# iom480ae register map
Registers are 32-bit, access not given, no defined reset value unless marked. A register's access mark holds for its fields unless they carry their own. Addresses are absolute; registers are grouped by the start of their names; [hi:lo] are bit positions.

## UUART0
0x400D0000 UUART0_UUART_CTL
  [2:0] FUNMODE
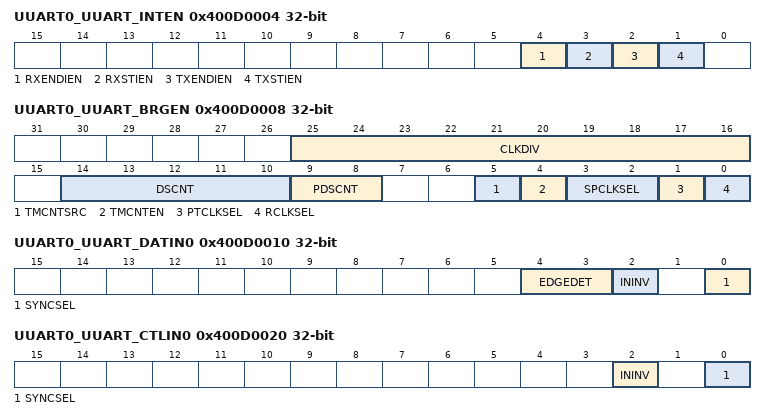
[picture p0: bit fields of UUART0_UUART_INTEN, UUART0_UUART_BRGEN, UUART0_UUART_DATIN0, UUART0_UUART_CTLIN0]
0x400D0004 UUART0_UUART_INTEN
  [4] RXENDIEN, [3] RXSTIEN, [2] TXENDIEN, [1] TXSTIEN
0x400D0008 UUART0_UUART_BRGEN
  [25:16] CLKDIV, [14:10] DSCNT, [9:8] PDSCNT, [5] TMCNTSRC, [4] TMCNTEN, [3:2] SPCLKSEL, [1] PTCLKSEL, [0] RCLKSEL
0x400D0010 UUART0_UUART_DATIN0
  [4:3] EDGEDET, [2] ININV, [0] SYNCSEL
0x400D0020 UUART0_UUART_CTLIN0
  [2] ININV, [0] SYNCSEL
0x400D0028 UUART0_UUART_CLKIN
  [0] SYNCSEL
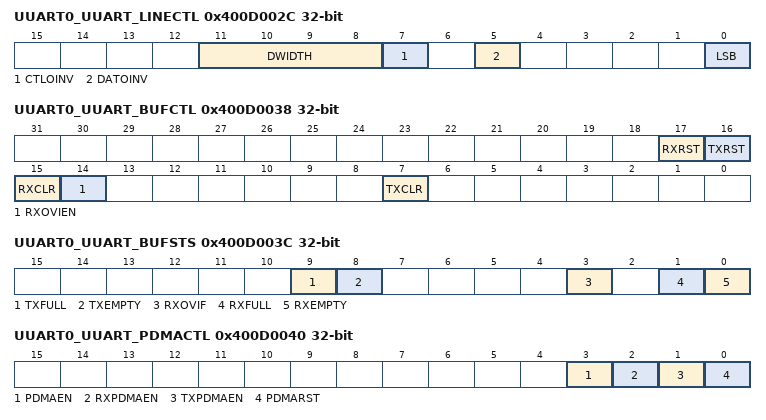
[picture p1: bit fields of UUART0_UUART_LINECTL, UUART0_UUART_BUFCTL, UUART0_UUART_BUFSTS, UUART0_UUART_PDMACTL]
0x400D002C UUART0_UUART_LINECTL
  [11:8] DWIDTH, [7] CTLOINV, [5] DATOINV, [0] LSB
0x400D0030 UUART0_UUART_TXDAT
  [15:0] TXDAT
0x400D0034 UUART0_UUART_RXDAT
  [15:0] RXDAT
0x400D0038 UUART0_UUART_BUFCTL
  [17] RXRST, [16] TXRST, [15] RXCLR, [14] RXOVIEN, [7] TXCLR
0x400D003C UUART0_UUART_BUFSTS
  [9] TXFULL, [8] TXEMPTY, [3] RXOVIF, [1] RXFULL, [0] RXEMPTY
0x400D0040 UUART0_UUART_PDMACTL
  [3] PDMAEN, [2] RXPDMAEN, [1] TXPDMAEN, [0] PDMARST
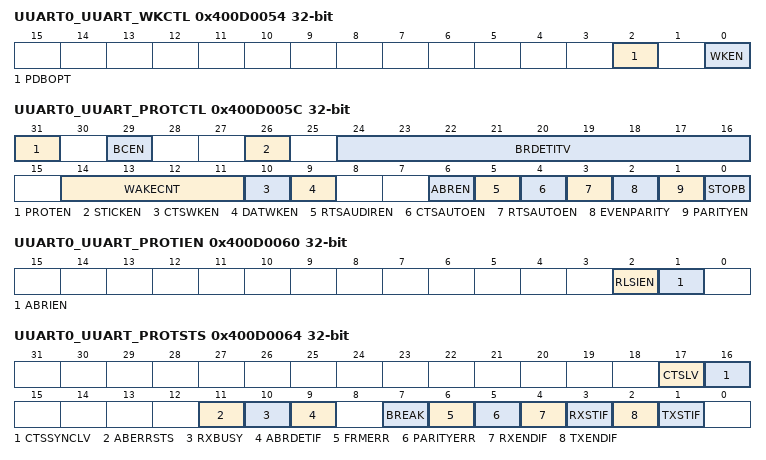
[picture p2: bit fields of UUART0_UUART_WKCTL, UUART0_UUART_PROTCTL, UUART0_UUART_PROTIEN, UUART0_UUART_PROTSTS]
0x400D0054 UUART0_UUART_WKCTL
  [2] PDBOPT, [0] WKEN
0x400D0058 UUART0_UUART_WKSTS
  [0] WKF
0x400D005C UUART0_UUART_PROTCTL
  [31] PROTEN, [29] BCEN, [26] STICKEN, [24:16] BRDETITV, [14:11] WAKECNT, [10] CTSWKEN, [9] DATWKEN, [6] ABREN, [5] RTSAUDIREN, [4] CTSAUTOEN, [3] RTSAUTOEN, [2] EVENPARITY, [1] PARITYEN, [0] STOPB
0x400D0060 UUART0_UUART_PROTIEN
  [2] RLSIEN, [1] ABRIEN
0x400D0064 UUART0_UUART_PROTSTS
  [17] CTSLV, [16] CTSSYNCLV, [11] ABERRSTS, [10] RXBUSY, [9] ABRDETIF, [7] BREAK, [6] FRMERR, [5] PARITYERR, [4] RXENDIF, [3] RXSTIF, [2] TXENDIF, [1] TXSTIF

## UUART1
0x400D1000 UUART1_UUART_CTL
  [2:0] FUNMODE
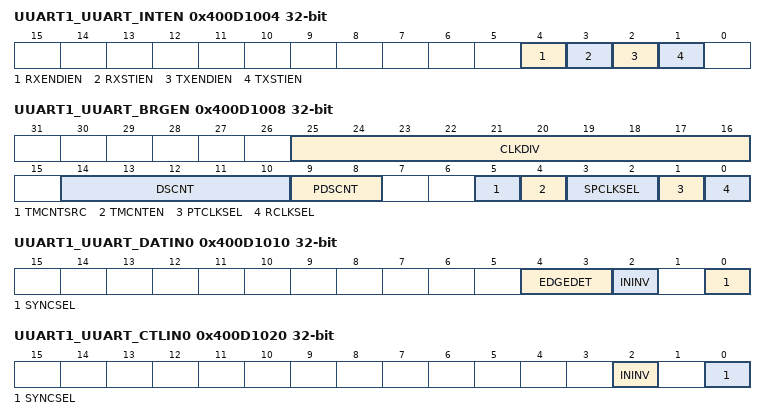
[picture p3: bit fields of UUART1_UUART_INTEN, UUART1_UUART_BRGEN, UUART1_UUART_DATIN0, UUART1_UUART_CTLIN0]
0x400D1004 UUART1_UUART_INTEN
  [4] RXENDIEN, [3] RXSTIEN, [2] TXENDIEN, [1] TXSTIEN
0x400D1008 UUART1_UUART_BRGEN
  [25:16] CLKDIV, [14:10] DSCNT, [9:8] PDSCNT, [5] TMCNTSRC, [4] TMCNTEN, [3:2] SPCLKSEL, [1] PTCLKSEL, [0] RCLKSEL
0x400D1010 UUART1_UUART_DATIN0
  [4:3] EDGEDET, [2] ININV, [0] SYNCSEL
0x400D1020 UUART1_UUART_CTLIN0
  [2] ININV, [0] SYNCSEL
0x400D1028 UUART1_UUART_CLKIN
  [0] SYNCSEL
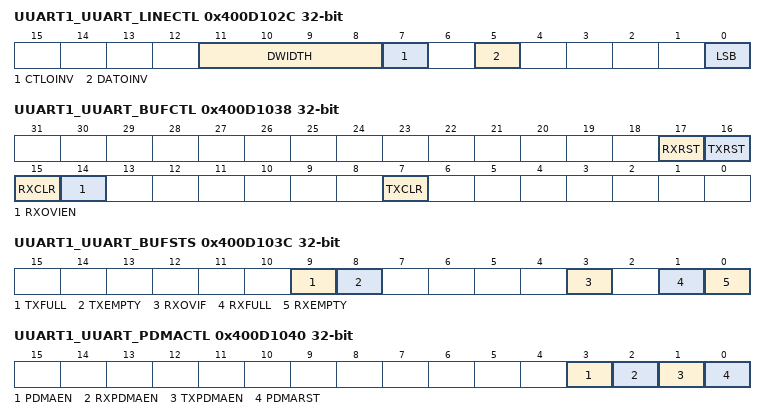
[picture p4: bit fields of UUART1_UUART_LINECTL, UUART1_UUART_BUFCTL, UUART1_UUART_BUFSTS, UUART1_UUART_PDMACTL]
0x400D102C UUART1_UUART_LINECTL
  [11:8] DWIDTH, [7] CTLOINV, [5] DATOINV, [0] LSB
0x400D1030 UUART1_UUART_TXDAT
  [15:0] TXDAT
0x400D1034 UUART1_UUART_RXDAT
  [15:0] RXDAT
0x400D1038 UUART1_UUART_BUFCTL
  [17] RXRST, [16] TXRST, [15] RXCLR, [14] RXOVIEN, [7] TXCLR
0x400D103C UUART1_UUART_BUFSTS
  [9] TXFULL, [8] TXEMPTY, [3] RXOVIF, [1] RXFULL, [0] RXEMPTY
0x400D1040 UUART1_UUART_PDMACTL
  [3] PDMAEN, [2] RXPDMAEN, [1] TXPDMAEN, [0] PDMARST
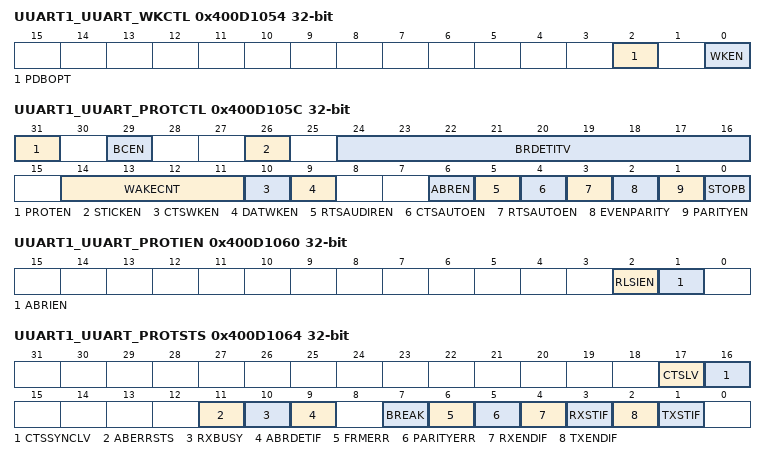
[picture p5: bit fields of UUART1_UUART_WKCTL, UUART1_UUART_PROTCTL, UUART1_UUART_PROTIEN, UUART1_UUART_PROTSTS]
0x400D1054 UUART1_UUART_WKCTL
  [2] PDBOPT, [0] WKEN
0x400D1058 UUART1_UUART_WKSTS
  [0] WKF
0x400D105C UUART1_UUART_PROTCTL
  [31] PROTEN, [29] BCEN, [26] STICKEN, [24:16] BRDETITV, [14:11] WAKECNT, [10] CTSWKEN, [9] DATWKEN, [6] ABREN, [5] RTSAUDIREN, [4] CTSAUTOEN, [3] RTSAUTOEN, [2] EVENPARITY, [1] PARITYEN, [0] STOPB
0x400D1060 UUART1_UUART_PROTIEN
  [2] RLSIEN, [1] ABRIEN
0x400D1064 UUART1_UUART_PROTSTS
  [17] CTSLV, [16] CTSSYNCLV, [11] ABERRSTS, [10] RXBUSY, [9] ABRDETIF, [7] BREAK, [6] FRMERR, [5] PARITYERR, [4] RXENDIF, [3] RXSTIF, [2] TXENDIF, [1] TXSTIF

## USPI0
0x400D0000 USPI0_USPI_CTL
  [2:0] FUNMODE
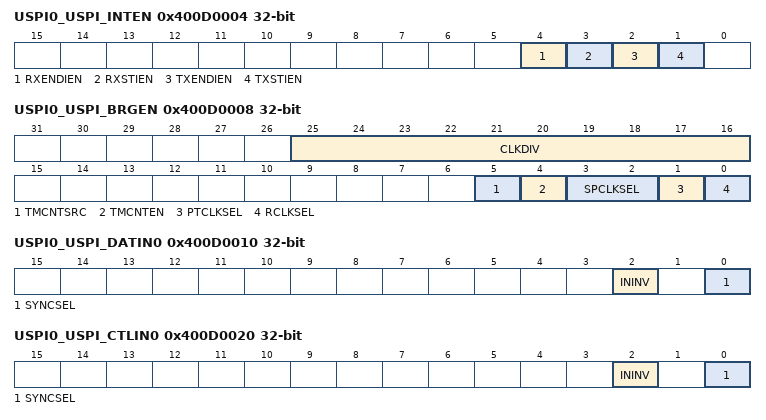
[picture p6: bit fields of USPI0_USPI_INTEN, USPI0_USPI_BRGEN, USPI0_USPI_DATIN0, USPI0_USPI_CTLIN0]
0x400D0004 USPI0_USPI_INTEN
  [4] RXENDIEN, [3] RXSTIEN, [2] TXENDIEN, [1] TXSTIEN
0x400D0008 USPI0_USPI_BRGEN
  [25:16] CLKDIV, [5] TMCNTSRC, [4] TMCNTEN, [3:2] SPCLKSEL, [1] PTCLKSEL, [0] RCLKSEL
0x400D0010 USPI0_USPI_DATIN0
  [2] ININV, [0] SYNCSEL
0x400D0020 USPI0_USPI_CTLIN0
  [2] ININV, [0] SYNCSEL
0x400D0028 USPI0_USPI_CLKIN
  [0] SYNCSEL
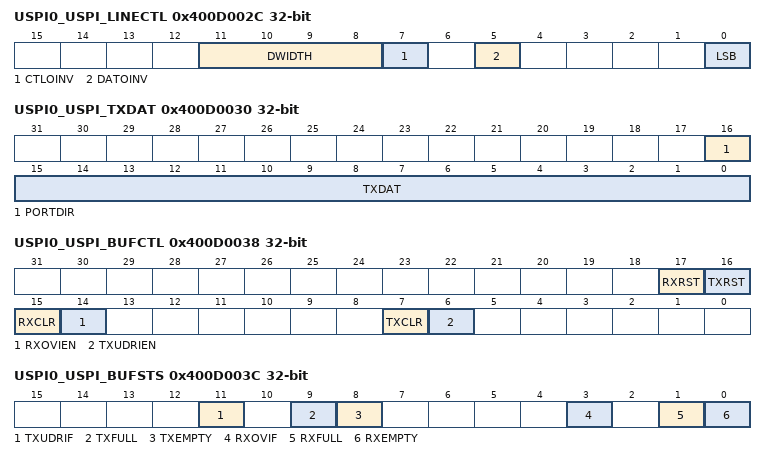
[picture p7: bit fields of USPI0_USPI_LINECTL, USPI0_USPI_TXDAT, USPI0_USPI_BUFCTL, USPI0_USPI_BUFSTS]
0x400D002C USPI0_USPI_LINECTL
  [11:8] DWIDTH, [7] CTLOINV, [5] DATOINV, [0] LSB
0x400D0030 USPI0_USPI_TXDAT
  [16] PORTDIR, [15:0] TXDAT
0x400D0034 USPI0_USPI_RXDAT
  [15:0] RXDAT
0x400D0038 USPI0_USPI_BUFCTL
  [17] RXRST, [16] TXRST, [15] RXCLR, [14] RXOVIEN, [7] TXCLR, [6] TXUDRIEN
0x400D003C USPI0_USPI_BUFSTS
  [11] TXUDRIF, [9] TXFULL, [8] TXEMPTY, [3] RXOVIF, [1] RXFULL, [0] RXEMPTY
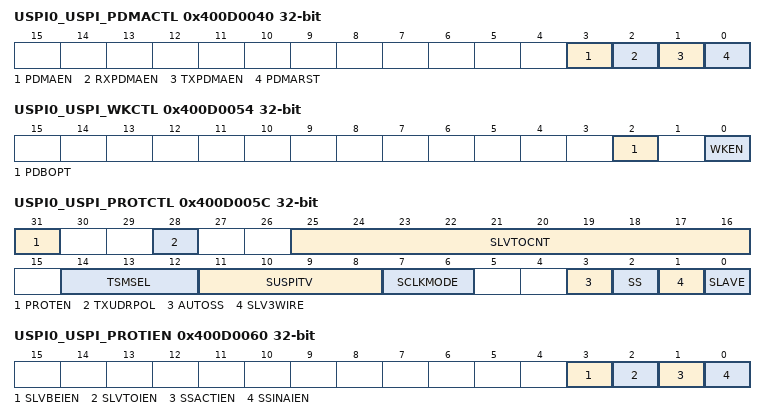
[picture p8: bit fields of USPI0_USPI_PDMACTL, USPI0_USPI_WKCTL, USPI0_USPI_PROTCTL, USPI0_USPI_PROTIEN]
0x400D0040 USPI0_USPI_PDMACTL
  [3] PDMAEN, [2] RXPDMAEN, [1] TXPDMAEN, [0] PDMARST
0x400D0054 USPI0_USPI_WKCTL
  [2] PDBOPT, [0] WKEN
0x400D0058 USPI0_USPI_WKSTS
  [0] WKF
0x400D005C USPI0_USPI_PROTCTL
  [31] PROTEN, [28] TXUDRPOL, [25:16] SLVTOCNT, [14:12] TSMSEL, [11:8] SUSPITV, [7:6] SCLKMODE, [3] AUTOSS, [2] SS, [1] SLV3WIRE, [0] SLAVE
0x400D0060 USPI0_USPI_PROTIEN
  [3] SLVBEIEN, [2] SLVTOIEN, [1] SSACTIEN, [0] SSINAIEN
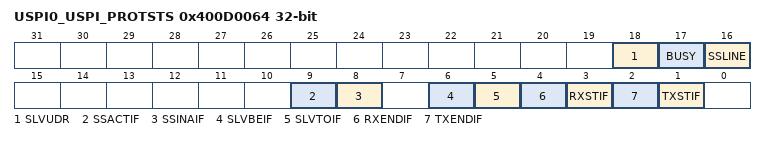
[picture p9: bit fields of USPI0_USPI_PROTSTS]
0x400D0064 USPI0_USPI_PROTSTS
  [18] SLVUDR, [17] BUSY, [16] SSLINE, [9] SSACTIF, [8] SSINAIF, [6] SLVBEIF, [5] SLVTOIF, [4] RXENDIF, [3] RXSTIF, [2] TXENDIF, [1] TXSTIF
